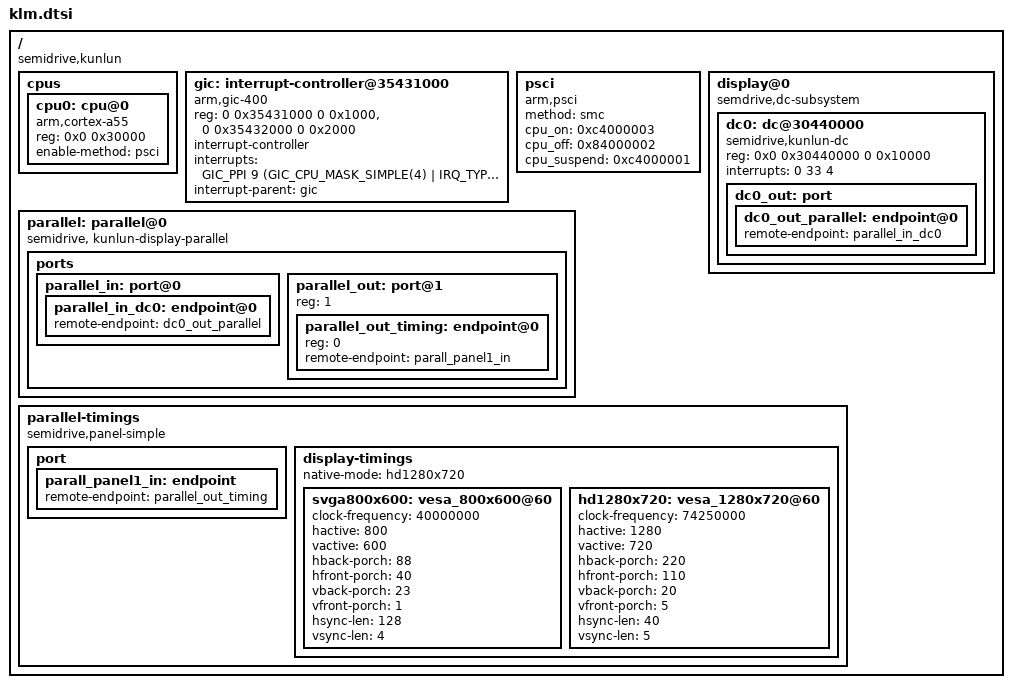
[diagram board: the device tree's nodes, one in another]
/*
 * Spreadtrum SC9836 SoC DTS file
 *
 * Copyright (C) 2014, Spreadtrum Communications Inc.
 *
 * This file is licensed under a dual GPLv2 or X11 license.
 */

#include "misc.dtsi"
#include <dt-bindings/interrupt-controller/arm-gic.h>

/ {
	compatible = "semidrive,kunlun";

	cpus {
		#address-cells = <2>;
		#size-cells = <0>;

		cpu0: cpu@0 {
			device_type = "cpu";
			compatible = "arm,cortex-a55", "arm,armv8";
			reg = <0x0 0x30000>;
			enable-method = "psci";
		};
/*
		cpu1: cpu@1 {
			device_type = "cpu";
			compatible = "arm,cortex-a55", "arm,armv8";
			reg = <0x0 0x1>;
			enable-method = "psci";
		};

		cpu2: cpu@2 {
			device_type = "cpu";
			compatible = "arm,cortex-a55", "arm,armv8";
			reg = <0x0 0x2>;
			enable-method = "psci";
		};

		cpu3: cpu@3 {
			device_type = "cpu";
			compatible = "arm,cortex-a55", "arm,armv8";
			reg = <0x0 0x3>;
			enable-method = "psci";
		};
*/
	};

	gic: interrupt-controller@35431000 {
		compatible = "arm,gic-400";
		reg = <0 0x35431000 0 0x1000>,
		      <0 0x35432000 0 0x2000>;
		#interrupt-cells = <3>;
		interrupt-controller;
		interrupts = <GIC_PPI 9 (GIC_CPU_MASK_SIMPLE(4) | IRQ_TYPE_LEVEL_HIGH)>;
		interrupt-parent = <&gic>;
	};

	psci {
		compatible	= "arm,psci";
		method		= "smc";
		cpu_on		= <0xc4000003>;
		cpu_off		= <0x84000002>;
		cpu_suspend	= <0xc4000001>;
	};


	display@0 {
		#address-cells = <2>;
		#size-cells = <2>;
		compatible = "semdrive,dc-subsystem";
		ranges;
		status = "okay";

		dc0: dc@30440000 {
			compatible = "semidrive,kunlun-dc";
			reg = <0x0 0x30440000 0 0x10000>;
			interrupts = <0 33 4>;
			status = "okay";
			
			dc0_out: port {
				dc0_out_parallel: endpoint@0 {
					remote-endpoint = <&parallel_in_dc0>;
				};
			};
		};
	};

	parallel: parallel@0 {
		compatible = "semidrive, kunlun-display-parallel";
		status = "okay";

		ports {
			#address-cells = <1>;
			#size-cells = <0>;
			parallel_in: port@0 {
				parallel_in_dc0: endpoint@0 {
					remote-endpoint = <&dc0_out_parallel>;
				};
			};

			parallel_out: port@1 {
				#address-cells = <1>;
				#size-cells = <0>;
				reg = <1>;
				parallel_out_timing: endpoint@0 {
					reg = <0>;
					remote-endpoint = <&parall_panel1_in>;
				};
			};
		};
	};

	parallel-timings {
		compatible = "semidrive,panel-simple";
		port {
			parall_panel1_in: endpoint {
				remote-endpoint = <&parallel_out_timing>;
			};
		};

		display-timings {
			native-mode = <&hd1280x720>;

			svga800x600: vesa_800x600@60 {
				clock-frequency = <40000000>;
				hactive = <800>;
				vactive = <600>;
				hback-porch = <88>;
				hfront-porch = <40>;
				vback-porch = <23>;
				vfront-porch = <1>;
				hsync-len = <128>;
				vsync-len = <4>;
			};

			hd1280x720: vesa_1280x720@60 {
				clock-frequency = <74250000>;
				hactive = <1280>;
				vactive = <720>;
				hback-porch = <220>;
				hfront-porch = <110>;
				vback-porch = <20>;
				vfront-porch = <5>;
				hsync-len = <40>;
				vsync-len = <5>;
			};
		};
	};


};
